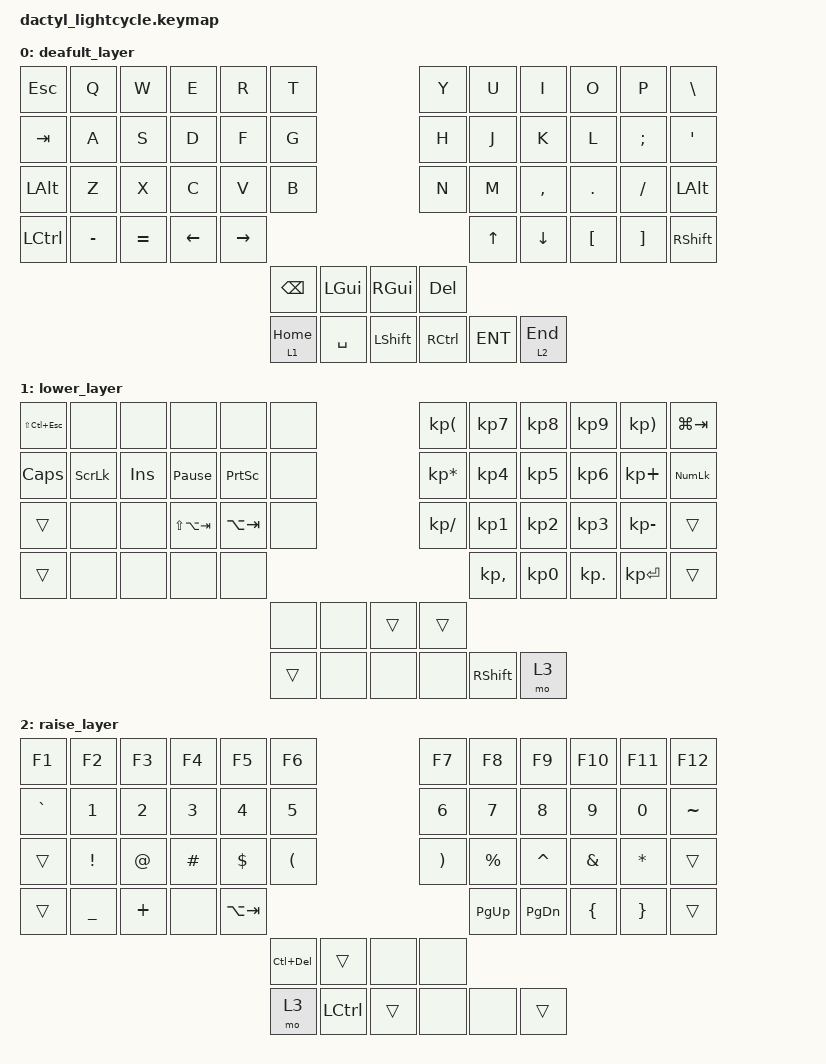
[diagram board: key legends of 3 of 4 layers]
/*
 * Copyright (c) 2023 Matt Adereth
 *
 * SPDX-License-Identifier: MIT
 */

#include <behaviors.dtsi>
#include <dt-bindings/zmk/keys.h>
#include <dt-bindings/zmk/bt.h>

/ {
        keymap {
                compatible = "zmk,keymap";

                deafult_layer {
//  ------ ----- ----- ----- ----- -----                             ----- ----- ----- ----- ----- -----
// | ESC |  Q  |  W  |  E  |  R  |  T  |                           |  Y  |  U  |  I  |  O  |  P  |  \  |
//  ------ ----- ----- ----- ----- -----                             ----- ----- ----- ----- ----- -----
// | TAB |  A  |  S  |  D  |  F  |  G  |                           |  H  |  J  |  K  |  L  |  ;  |  '  |
//  ----- ----- ----- ----- ----- -----                             ----- ----- ----- ----- ----- -----
// | ALT |  Z  |  X  |  C  |  V  |  B  |                           |  N  |  M  |  ,  |  .  |  /  | ALT |
//  ----- ----- ----- ----- ----- -----                             ----- ----- ----- ----- ----- -----
// | CTL |  -  |  =  |  ←  |  →  |                                       |  ↑  |  ↓  |  [  |  ]  | SFT |
//  ----- ----- ----- ----- -----       ----- -----     ----- -----       ----- ----- ----- ----- -----
//                                -----| BSP | GUI |   | GUI | DEL |-----
//                               |     |     |     |   |     |     |     |
//                               | HOM |----- -----     ----- -----| END |
//                               |(lt1)| SPC | SFT |   | CTL | ENT |(lt2)|
//                               |     |     |     |   |     |     |     |
//                                ----- ----- -----     ----- ----- -----
                        bindings = <
   &kp ESC   &kp Q     &kp W     &kp E     &kp R     &kp T                                         &kp Y  &kp U  &kp I     &kp O    &kp P    &kp BSLH
   &kp TAB   &kp A     &kp S     &kp D     &kp F     &kp G                                         &kp H  &kp J  &kp K     &kp L    &kp SEMI &kp SQT
   &kp LALT  &kp Z     &kp X     &kp C     &kp V     &kp B                                         &kp N  &kp M  &kp COMMA &kp DOT  &kp FSLH &kp LALT
   &kp LCTRL &kp MINUS &kp EQUAL &kp LEFT  &kp RIGHT                                                      &kp UP &kp DOWN  &kp LBKT &kp RBKT &kp RSHFT
                                                            &kp BSPC  &kp LGUI   &kp RGUI  &kp DEL
                                                 &lt 1 HOME &kp SPACE &kp LSHFT  &kp RCTRL &kp ENT &lt 2 END
                        >;
                };

                lower_layer {
//  ----- ----- ----- ----- ----- -----                             ----- ----- ----- ----- ----- -----
// |scESC|     |     |     |     |     |                           | KP( | KP7 | KP8 | KP9 | KP) |G_TB |
//  ----- ----- ----- ----- ----- -----                             ----- ----- ----- ----- ----- -----
// | CAP | SLK | INS | BRK | PSC |     |                           | KP* | KP4 | KP5 | KP6 | KP+ | NLK |
//  ----- ----- ----- ----- ----- -----                             ----- ----- ----- ----- ----- -----
// |  ◌  |     |     |saTAB|aTAB |     |                           | KP/ | KP1 | KP2 | KP3 | KP- |  ◌  |
//  ----- ----- ----- ----- ----- -----                             ----- ----- ----- ----- ----- -----
// |  ◌  |     |     |     |     |                                       | KP, | KP0 | KP. | KP↵ |  ◌  |
//  ----- ----- ----- ----- -----       ----- -----     ----- -----       ----- ----- ----- ----- -----
//                                -----|     |     |   |  ◌  |C_BPC|-----
//                               |     |     |     |   |     |     |     |
//                               |  ◌  |----- -----     ----- -----| mo3 |
//                               |     |     |     |   |  ◌  | SFT |     |
//                               |     |     |     |   |     |     |     |
//                                ----- ----- -----     ----- ----- -----
                        bindings = <
   &kp LS(LC(ESC)) &none    &none   &none           &none       &none                                &kp KP_LPAR     &kp KP_N7    &kp KP_N8 &kp KP_N9  &kp KP_RPAR  &kp LG(TAB)
   &kp CAPS        &kp SLCK &kp INS &kp PAUSE_BREAK &kp PSCRN   &none                                &kp KP_ASTERISK &kp KP_N4    &kp KP_N5 &kp KP_N6  &kp KP_PLUS  &kp KP_NUM
   &trans          &none    &none   &kp LS(LA(TAB)) &kp LA(TAB) &none                                &kp KP_SLASH    &kp KP_N1    &kp KP_N2 &kp KP_N3  &kp KP_MINUS &trans
   &trans          &none    &none   &none           &none                                                            &kp KP_COMMA &kp KP_N0 &kp KP_DOT &kp KP_ENTER &trans
                                                                       &none &none  &trans &trans
                                                                &trans &none &none  &none  &kp RSHFT &mo 3
                        >;
                };

                raise_layer {
//  ----- ----- ----- ----- ----- -----                             ----- ----- ----- ----- ----- -----
// | F1  | F2  | F3  | F4  | F5  | F6  |                           | F7  | F8  | F9  | F10 | F11 | F12 |
//  ----- ----- ----- ----- ----- -----                             ----- ----- ----- ----- ----- -----
// |  `  |  1  |  2  |  3  |  4  |  5  |                           |  6  |  7  |  8  |  9  |  0  |  ~  |
//  ----- ----- ----- ----- ----- -----                             ----- ----- ----- ----- ----- -----
// |  ◌  |  !  |  @  |  #  |  $  |  (  |                           |  )  |  %  |  ^  |  &  |  *  |  ◌  |
//  ----- ----- ----- ----- ----- -----                             ----- ----- ----- ----- ----- -----
// |  ◌  |  _  |  +  |     |A_TAB|                                       | PG↑ | PG↓ |  {  |  }  |  ◌  |
//  ----- ----- ----- ----- -----       ----- -----     ----- -----       ----- ----- ----- ----- -----
//                                -----|C_DEL|  ◌  |   |     |     |-----
//                               |     |     |     |   |     |     |     |
//                               | mo3 |----- -----     ----- -----|  ◌  |
//                               |     | CTL |  ◌  |   |     |     |     |
//                               |     |     |     |   |     |     |     |
//                                ----- ----- -----     ----- ----- -----
                        bindings = <
   &kp F1    &kp F2    &kp F3   &kp F4   &kp F5      &kp F6                                &kp F7   &kp F8    &kp F9    &kp F10  &kp F11  &kp F12
   &kp GRAVE &kp N1    &kp N2   &kp N3   &kp N4      &kp N5                                &kp N6   &kp N7    &kp N8    &kp N9   &kp N0   &kp TILDE
   &trans    &kp EXCL  &kp AT   &kp HASH &kp DLLR    &kp LPAR                              &kp RPAR &kp PRCNT &kp CARET &kp AMPS &kp STAR &trans
   &trans    &kp UNDER &kp PLUS &none    &kp LA(TAB)                                                &kp PG_UP &kp PG_DN &kp LBRC &kp RBRC &trans
                                                           &kp LC(DEL) &trans  &none &none
                                                     &mo 3 &kp LCTRL   &trans  &none &none &trans
                        >;
                };

                system_layer {
//  ----- ----- ----- ----- ----- -----                             ----- ----- ----- ----- ----- -----
// |     |     |     |     |     |     |                           |     | VL+ |     | BR+ |     |     |
//  ----- ----- ----- ----- ----- -----                             ----- ----- ----- ----- ----- -----
// | BT5 | BT4 | BT3 | BT2 | BT1 |     |                           |     | VLm | mNT | mPP | mPV |     |
//  ----- ----- ----- ----- ----- -----                             ----- ----- ----- ----- ----- -----
// | BTC |     |     |     |     |     |                           |     | VL- |     | BR- |     |     |
//  ----- ----- ----- ----- ----- -----                             ----- ----- ----- ----- ----- -----
// |     |     |     | RST | BLR |                                       | BLR | RST |     |     |     |
//  ----- ----- ----- ----- -----       ----- -----     ----- -----       ----- ----- ----- ----- -----
//                                -----|     |     |   |     |     |-----
//                               |     |     |     |   |     |     |     |
//                               |  ◌  |----- -----     ----- -----|  ◌  |
//                               |     |     |     |   |     |     |     |
//                               |     |     |     |   |     |     |     |
//                                ----- ----- -----     ----- ----- -----
                        bindings = <
   &none        &none        &none        &none        &none        &none                           &none  &none        &none      &none        &none      &none
   &none        &none        &none        &none        &none        &none                           &none  &kp C_VOL_UP &none      &kp C_BRI_UP &none      &none
   &bt BT_SEL 5 &bt BT_SEL 4 &bt BT_SEL 3 &bt BT_SEL 2 &bt BT_SEL 1 &none                           &none  &kp C_MUTE   &kp C_NEXT &kp C_PP     &kp C_PREV &none
   &bt BT_CLR   &none        &none        &none        &none        &none                           &none  &kp C_VOL_DN &none      &kp C_BRI_DN &none      &none
   &none        &none        &none        &sys_reset   &bootloader                                         &bootloader  &sys_reset &none        &none      &none
                                                                           &none &none  &none &none
                                                                    &trans &none &none  &none &none &trans
                                                                                 &none  &none
                        >;
                };
        };
};
